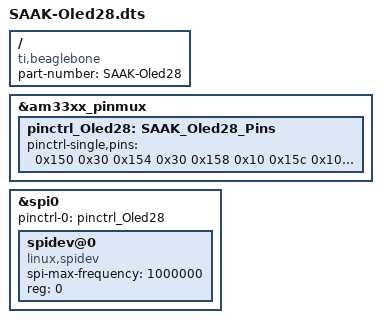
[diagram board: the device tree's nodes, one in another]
/*  
* Copyright (C) 2012 Texas Instruments Incorporated - http://www.ti.com/
*
* This program is free software; you can redistribute it and/or modify
* it under the terms of the GNU General Purpose License Version 2 as
* published by the Free Software Foundation
*
* by Saak Dertadian (s.dertadian@gmail.com)
*
* Cape Oled 2.8' for Beaglebone
* usind Oled 256x64 (Newhaven: NHD‐2.8‐25664UMB2)
*
*/

/dts-v1/;
/plugin/;

/ {
	compatible = "ti,beaglebone", "ti,beaglebone-black";

	/* identification */
	part-number = "SAAK-Oled28";

	fragment@0
	{
		target = <&am33xx_pinmux>;
		__overlay__
		{
			pinctrl_Oled28: SAAK_Oled28_Pins
			{
				pinctrl-single,pins = <
					0x150 0x30  /* spi0_sclk, INPUT_PULLUP  | MODE0 */
					0x154 0x30  /* spi0_d0,   INPUT_PULLUP  | MODE0 */
					0x158 0x10  /* spi0_d1,   OUTPUT_PULLUP | MODE0 */
					0x15c 0x10  /* spi0_cs0,  OUTPUT_PULLUP | MODE0 */

					0x044 0x7F  /* P9_23  49  OUTPUT MODE7 - DC  */
					0x078 0x7F  /* P9_12  60  OUTPUT MODE7 - RS  */
								
					/* OUTPUT  GPIO(mode7) 0x07 pulldown, 0x17 pullup, 0x?f no pullup/down */
					/* INPUT   GPIO(mode7) 0x27 pulldown, 0x37 pullup, 0x?f no pullup/down */
				>;
			};
		};
	};

	fragment@1
	{
		target = <&spi0>;
		__overlay__
		{
			#address-cells = <1>;
			#size-cells = <0>;

			status = "okay";
			pinctrl-names = "default";
			pinctrl-0 = <&pinctrl_Oled28>;

			spidev@0
			{
				spi-max-frequency = <1000000>;
				reg = <0>;
				compatible = "linux,spidev";
			};
		};
	};
};
